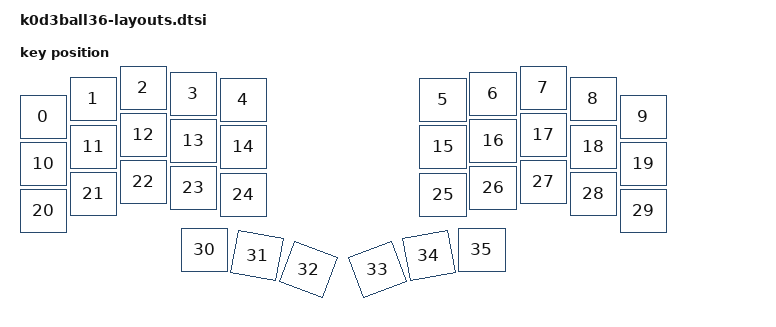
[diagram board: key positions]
/*
 * Physical layout of k0d3ball36. Generated by scripts/gen_physical_layout.py
 * from the geometry in docs/01-design-spec.md; do not edit by hand.
 *
 * Key order equals the matrix transform order: three finger rows (left pinky
 * to left inner, then right inner to right pinky) followed by the six thumb keys.
 */

#include <physical_layouts.dtsi>

/ {
    k0d3ball36_layout: k0d3ball36_layout {
        compatible = "zmk,physical-layout";
        display-name = "k0d3ball36";

        keys  //                     w   h    x    y     rot    rx    ry
            = <&key_physical_attrs  100   94     0    58       0     0     0>
            , <&key_physical_attrs  100   94   100    23       0     0     0>
            , <&key_physical_attrs  100   94   200     0       0     0     0>
            , <&key_physical_attrs  100   94   300    12       0     0     0>
            , <&key_physical_attrs  100   94   400    25       0     0     0>
            , <&key_physical_attrs  100   94   800    25       0     0     0>
            , <&key_physical_attrs  100   94   900    12       0     0     0>
            , <&key_physical_attrs  100   94  1000     0       0     0     0>
            , <&key_physical_attrs  100   94  1100    23       0     0     0>
            , <&key_physical_attrs  100   94  1200    58       0     0     0>
            , <&key_physical_attrs  100   94     0   152       0     0     0>
            , <&key_physical_attrs  100   94   100   118       0     0     0>
            , <&key_physical_attrs  100   94   200    94       0     0     0>
            , <&key_physical_attrs  100   94   300   107       0     0     0>
            , <&key_physical_attrs  100   94   400   119       0     0     0>
            , <&key_physical_attrs  100   94   800   119       0     0     0>
            , <&key_physical_attrs  100   94   900   107       0     0     0>
            , <&key_physical_attrs  100   94  1000    94       0     0     0>
            , <&key_physical_attrs  100   94  1100   118       0     0     0>
            , <&key_physical_attrs  100   94  1200   152       0     0     0>
            , <&key_physical_attrs  100   94     0   247       0     0     0>
            , <&key_physical_attrs  100   94   100   212       0     0     0>
            , <&key_physical_attrs  100   94   200   189       0     0     0>
            , <&key_physical_attrs  100   94   300   201       0     0     0>
            , <&key_physical_attrs  100   94   400   214       0     0     0>
            , <&key_physical_attrs  100   94   800   214       0     0     0>
            , <&key_physical_attrs  100   94   900   201       0     0     0>
            , <&key_physical_attrs  100   94  1000   189       0     0     0>
            , <&key_physical_attrs  100   94  1100   212       0     0     0>
            , <&key_physical_attrs  100   94  1200   247       0     0     0>
            , <&key_physical_attrs  100   94   322   325       0     0     0>
            , <&key_physical_attrs  100   94   428   336    1000   478   383>
            , <&key_physical_attrs  100   94   531   364    2000   581   411>
            , <&key_physical_attrs  100   94   669   364 (-2000)   719   411>
            , <&key_physical_attrs  100   94   772   336 (-1000)   822   383>
            , <&key_physical_attrs  100   94   878   325       0     0     0>
            ;
    };
};
